VERSION ""

NS_ :

BS_:

BU_:
VAL_TABLE_ amps_data 33 "Description for the value '0x21'" 32 "Description for the value '0x20'" 31 "Description for the value '0x1F'" 30 "Description for the value '0x1E'" 29 "Description for the value '0x1D'" 28 "Description for the value '0x1C'" 27 "Description for the value '0x1B'" 26 "Description for the value '0x1A'" 25 "Description for the value '0x19'" 24 "Description for the value '0x18'" 23 "Description for the value '0x17'" 22 "Description for the value '0x16'" 21 "Description for the value '0x15'" 20 "Description for the value '0x14'" 19 "Description for the value '0x13'" 18 "Description for the value '0x12'" 17 "Description for the value '0x11'" 16 "Description for the value '0x10'" 15 "Description for the value '0xF'" 14 "Description for the value '0xE'" 13 "Description for the value '0xD'" 12 "Description for the value '0xC'" 11 "Description for the value '0xB'" 10 "Description for the value '0xA'" 9 "Description for the value '0x9'" 8 "Description for the value '0x8'" 7 "Description for the value '0x7'" 6 "Description for the value '0x6'" 5 "Description for the value '0x5'" 4 "Description for the value '0x4'" 3 "Description for the value '0x3'" 2 "Description for the value '0x2'" 1 "Description for the value '0x1'" 0 "Description for the value '0x0'" ;

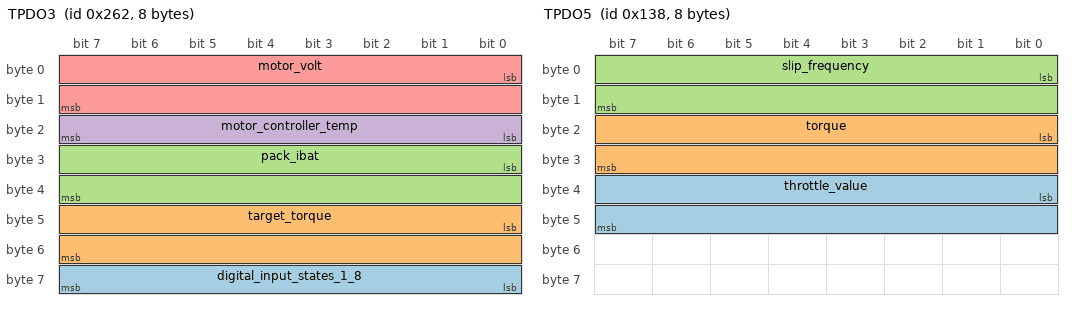
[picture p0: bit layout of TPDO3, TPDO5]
BO_ 610 TPDO3: 8 Vector__XXX
 SG_ digital_input_states_1_8 : 56|8@1+ (1,0) [0|0] "" Vector__XXX
 SG_ target_torque : 40|16@1- (0.1,0) [-1000|1000] "Nm" Vector__XXX
 SG_ pack_ibat : 24|16@1- (0.0625,0) [-1000|500] "A" Vector__XXX
 SG_ motor_controller_temp : 16|8@1- (1,0) [-128|127] "C" Vector__XXX
 SG_ motor_volt : 0|16@1+ (0.0625,0) [0|65535] "V" Vector__XXX

BO_ 312 TPDO5: 8 Vector__XXX
 SG_ throttle_value : 32|16@1- (3.05185E-005,0) [-32768|32767] "" Vector__XXX
 SG_ torque : 16|16@1- (0.1,0) [-1000|1000] "Nm" Vector__XXX
 SG_ slip_frequency : 0|16@1- (0.024543693,0) [-32768|32767] "rads/sec" Vector__XXX

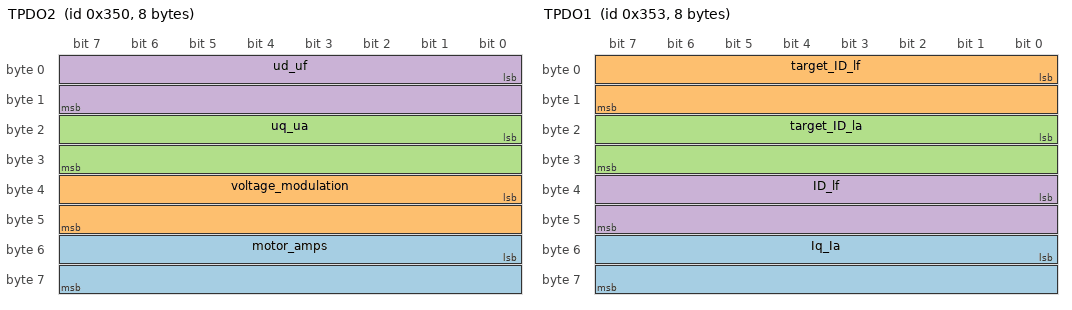
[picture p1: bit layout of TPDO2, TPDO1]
BO_ 848 TPDO2: 8 Vector__XXX
 SG_ motor_amps : 48|16@1- (1,0) [-1000|1000] "A(RMS)" Vector__XXX
 SG_ voltage_modulation : 32|16@1- (0.392156862745098,0) [0|255] "%" Vector__XXX
 SG_ uq_ua : 16|16@1- (0.0625,0) [-3200|3200] "V" Vector__XXX
 SG_ ud_uf : 0|16@1- (0.0625,0) [-3200|3200] "V" Vector__XXX

BO_ 851 TPDO1: 8 Vector__XXX
 SG_ Iq_Ia : 48|16@1- (0.0625,0) [-32000|32000] "A" Vector__XXX
 SG_ target_ID_lf : 0|16@1- (0.0625,0) [-32768|32767] "A" Vector__XXX
 SG_ target_ID_la : 16|16@1- (0.0625,0) [-32000|32000] "A" Vector__XXX
 SG_ ID_lf : 32|16@1- (0.0625,0) [-32768|32767] "A" Vector__XXX

BO_ 1088 TPDO4: 8 Vector__XXX
 SG_ target_velocity_left_motor : 0|32@1- (1,0) [-2147483648|2147483647] "rpm" Vector__XXX
 SG_ motor_rpm : 32|16@1- (1,0) [0|8000] "rpm" Vector__XXX
